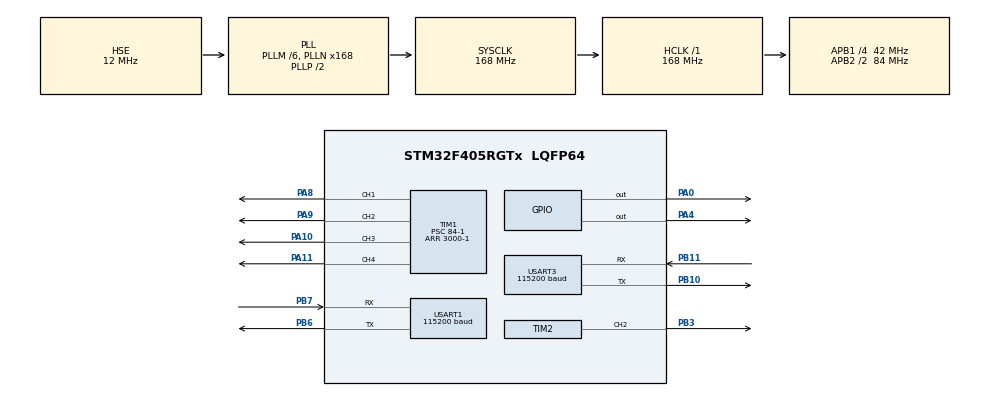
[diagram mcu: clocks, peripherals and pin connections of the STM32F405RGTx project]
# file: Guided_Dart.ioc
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Dma.Request0=USART3_RX
Dma.Request1=USART3_TX
Dma.Request2=USART1_RX
Dma.Request3=USART1_TX
Dma.USART1_RX.2.Direction=DMA_PERIPH_TO_MEMORY
Dma.USART1_RX.2.FIFOMode=DMA_FIFOMODE_DISABLE
Dma.USART1_RX.2.Instance=DMA2_Stream2
Dma.USART1_RX.2.MemDataAlignment=DMA_MDATAALIGN_BYTE
Dma.USART1_RX.2.MemInc=DMA_MINC_ENABLE
Dma.USART1_RX.2.Mode=DMA_NORMAL
Dma.USART1_RX.2.PeriphDataAlignment=DMA_PDATAALIGN_BYTE
Dma.USART1_RX.2.PeriphInc=DMA_PINC_DISABLE
Dma.USART1_RX.2.Priority=DMA_PRIORITY_LOW
Dma.USART1_TX.3.Direction=DMA_MEMORY_TO_PERIPH
Dma.USART1_TX.3.FIFOMode=DMA_FIFOMODE_DISABLE
Dma.USART1_TX.3.Instance=DMA2_Stream7
Dma.USART1_TX.3.MemDataAlignment=DMA_MDATAALIGN_BYTE
Dma.USART1_TX.3.MemInc=DMA_MINC_ENABLE
Dma.USART1_TX.3.Mode=DMA_NORMAL
Dma.USART1_TX.3.PeriphDataAlignment=DMA_PDATAALIGN_BYTE
Dma.USART1_TX.3.PeriphInc=DMA_PINC_DISABLE
Dma.USART1_TX.3.Priority=DMA_PRIORITY_LOW
Dma.USART3_RX.0.Direction=DMA_PERIPH_TO_MEMORY
Dma.USART3_RX.0.FIFOMode=DMA_FIFOMODE_DISABLE
Dma.USART3_RX.0.Instance=DMA1_Stream1
Dma.USART3_RX.0.MemDataAlignment=DMA_MDATAALIGN_BYTE
Dma.USART3_RX.0.MemInc=DMA_MINC_ENABLE
Dma.USART3_RX.0.Mode=DMA_NORMAL
Dma.USART3_RX.0.PeriphDataAlignment=DMA_PDATAALIGN_BYTE
Dma.USART3_RX.0.PeriphInc=DMA_PINC_DISABLE
Dma.USART3_RX.0.Priority=DMA_PRIORITY_LOW
Dma.USART3_TX.1.Direction=DMA_MEMORY_TO_PERIPH
Dma.USART3_TX.1.FIFOMode=DMA_FIFOMODE_DISABLE
Dma.USART3_TX.1.Instance=DMA1_Stream3
Dma.USART3_TX.1.MemDataAlignment=DMA_MDATAALIGN_BYTE
Dma.USART3_TX.1.MemInc=DMA_MINC_ENABLE
Dma.USART3_TX.1.Mode=DMA_NORMAL
Dma.USART3_TX.1.PeriphDataAlignment=DMA_PDATAALIGN_BYTE
Dma.USART3_TX.1.PeriphInc=DMA_PINC_DISABLE
Dma.USART3_TX.1.Priority=DMA_PRIORITY_LOW
Mcu.Family=STM32F4
Mcu.Name=STM32F405RGTx
Mcu.Package=LQFP64
NVIC.DMA1_Stream1_IRQn=true\:0\:0\:false\:false\:true\:false\:true\:true
NVIC.DMA1_Stream3_IRQn=true\:0\:0\:false\:false\:true\:false\:true\:true
NVIC.DMA2_Stream2_IRQn=true\:0\:0\:false\:false\:true\:false\:true\:true
NVIC.DMA2_Stream7_IRQn=true\:0\:0\:false\:false\:true\:false\:true\:true
NVIC.PriorityGroup=NVIC_PRIORITYGROUP_4
NVIC.USART1_IRQn=true\:0\:0\:false\:false\:true\:true\:true\:true
NVIC.USART3_IRQn=true\:0\:0\:false\:false\:true\:true\:true\:true
PA0-WKUP.GPIO_PuPd=GPIO_PULLDOWN
PA0-WKUP.PinState=GPIO_PIN_SET
PA0-WKUP.Signal=GPIO_Output
PA10.Signal=S_TIM1_CH3
PA11.Signal=S_TIM1_CH4
PA13.Mode=Serial_Wire
PA13.Signal=SYS_JTMS-SWDIO
PA14.Mode=Serial_Wire
PA14.Signal=SYS_JTCK-SWCLK
PA4.GPIO_PuPd=GPIO_PULLDOWN
PA4.GPIO_Speed=GPIO_SPEED_FREQ_VERY_HIGH
PA4.Signal=GPIO_Output
PA8.Signal=S_TIM1_CH1
PA9.Signal=S_TIM1_CH2
PB10.Mode=Asynchronous
PB10.Signal=USART3_TX
PB11.Mode=Asynchronous
PB11.Signal=USART3_RX
PB3.Signal=S_TIM2_CH2
PB6.Mode=Asynchronous
PB6.Signal=USART1_TX
PB7.Mode=Asynchronous
PB7.Signal=USART1_RX
PH0-OSC_IN.Mode=HSE-External-Oscillator
PH0-OSC_IN.Signal=RCC_OSC_IN
PH1-OSC_OUT.Mode=HSE-External-Oscillator
PH1-OSC_OUT.Signal=RCC_OSC_OUT
ProjectManager.HeapSize=0x200
ProjectManager.StackSize=0x400
ProjectManager.TargetToolchain=Makefile
RCC.48MHZClocksFreq_Value=84000000
RCC.AHBFreq_Value=168000000
RCC.APB1CLKDivider=RCC_HCLK_DIV4
RCC.APB1Freq_Value=42000000
RCC.APB1TimFreq_Value=84000000
RCC.APB2CLKDivider=RCC_HCLK_DIV2
RCC.APB2Freq_Value=84000000
RCC.APB2TimFreq_Value=168000000
RCC.CortexFreq_Value=168000000
RCC.HCLKFreq_Value=168000000
RCC.HSE_VALUE=12000000
RCC.HSI_VALUE=16000000
RCC.LSE_VALUE=32768
RCC.PLLM=6
RCC.PLLN=168
RCC.PLLSourceVirtual=RCC_PLLSOURCE_HSE
RCC.SYSCLKFreq_VALUE=168000000
RCC.SYSCLKSource=RCC_SYSCLKSOURCE_PLLCLK
RCC.VCOOutputFreq_Value=336000000
SH.S_TIM1_CH1.0=TIM1_CH1,PWM Generation1 CH1
SH.S_TIM1_CH2.0=TIM1_CH2,PWM Generation2 CH2
SH.S_TIM1_CH3.0=TIM1_CH3,PWM Generation3 CH3
SH.S_TIM1_CH4.0=TIM1_CH4,PWM Generation4 CH4
SH.S_TIM2_CH2.0=TIM2_CH2,PWM Generation2 CH2
STMicroelectronics.X-CUBE-ALGOBUILD.1.4.0.LibraryCcDSPOoLibraryJjDSPOoLibrary=true
TIM1.Channel-PWM\ Generation1\ CH1=TIM_CHANNEL_1
TIM1.Channel-PWM\ Generation2\ CH2=TIM_CHANNEL_2
TIM1.Channel-PWM\ Generation3\ CH3=TIM_CHANNEL_3
TIM1.Channel-PWM\ Generation4\ CH4=TIM_CHANNEL_4
TIM1.Period=3000-1
TIM1.Prescaler=84-1
TIM2.Channel-PWM\ Generation2\ CH2=TIM_CHANNEL_2
TIM2.Period=20000-1
TIM2.Prescaler=84-1
USART1.BaudRate=115200
USART1.VirtualMode=VM_ASYNC
USART3.BaudRate=115200
USART3.VirtualMode=VM_ASYNC
VP_STMicroelectronics.X-CUBE-ALGOBUILD_VS_DSPOoLibraryJjLibrary_1.4.0_1.4.0.Mode=DSPOoLibraryJjLibrary
VP_TIM1_VS_ClockSourceINT.Mode=Internal
VP_TIM2_VS_ClockSourceINT.Mode=Internal
board=custom

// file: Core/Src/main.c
/* USER CODE BEGIN Header */
/**
  ******************************************************************************
  * @file           : main.c
  * @brief          : Main program body
  ******************************************************************************
  * @attention
  *
  * <h2><center>&copy; Copyright (c) 2025 STMicroelectronics.
  * All rights reserved.</center></h2>
  *
  * This software component is licensed by ST under BSD 3-Clause license,
  * the "License"; You may not use this file except in compliance with the
  * License. You may obtain a copy of the License at:
  *                        opensource.org/licenses/BSD-3-Clause
  *
  ******************************************************************************
  */
/* USER CODE END Header */
#include "main.h"
#include "dma.h"
#include "tim.h"
#include "usart.h"
#include "gpio.h"

/* USER CODE BEGIN Includes */
#include "JY61P.h"  // 传感器头文件
#include "servo_motor.h" // 舵机头文�?
#include"openmv.h" // openmv头文�?
#include"Ducted_fan_Motor.h" // 电机头文�?
/* USER CODE END Includes */

void SystemClock_Config(void);

int main(void)
{

  /* MCU Configuration--------------------------------------------------------*/

  /* Reset of all peripherals, Initializes the Flash interface and the Systick. */
  HAL_Init();

  /* Configure the system clock */
  SystemClock_Config();

  /* Initialize all configured peripherals */
  MX_GPIO_Init();
  MX_DMA_Init();
  MX_USART3_UART_Init();
  MX_TIM1_Init();
  MX_USART1_UART_Init();
  MX_TIM2_Init();

  /* Infinite loop */
  /* USER CODE BEGIN WHILE */
  while (1)
  {
    // Servo_Motor_Task(0, 0, 0, 0); // 舵机任务
    /* USER CODE END WHILE */

  }
}

void SystemClock_Config(void)
{
  RCC_OscInitTypeDef RCC_OscInitStruct = {0};
  RCC_ClkInitTypeDef RCC_ClkInitStruct = {0};

  /** Configure the main internal regulator output voltage
  */
  __HAL_RCC_PWR_CLK_ENABLE();
  __HAL_PWR_VOLTAGESCALING_CONFIG(PWR_REGULATOR_VOLTAGE_SCALE1);

  /** Initializes the RCC Oscillators according to the specified parameters
  * in the RCC_OscInitTypeDef structure.
  */
  RCC_OscInitStruct.OscillatorType = RCC_OSCILLATORTYPE_HSE;
  RCC_OscInitStruct.HSEState = RCC_HSE_ON;
  RCC_OscInitStruct.PLL.PLLState = RCC_PLL_ON;
  RCC_OscInitStruct.PLL.PLLSource = RCC_PLLSOURCE_HSE;
  RCC_OscInitStruct.PLL.PLLM = 6;
  RCC_OscInitStruct.PLL.PLLN = 168;
  RCC_OscInitStruct.PLL.PLLP = RCC_PLLP_DIV2;
  RCC_OscInitStruct.PLL.PLLQ = 4;
  if (HAL_RCC_OscConfig(&RCC_OscInitStruct) != HAL_OK)
  {
    Error_Handler();
  }

  /** Initializes the CPU, AHB and APB buses clocks
  */
  RCC_ClkInitStruct.ClockType = RCC_CLOCKTYPE_HCLK|RCC_CLOCKTYPE_SYSCLK
                              |RCC_CLOCKTYPE_PCLK1|RCC_CLOCKTYPE_PCLK2;
  RCC_ClkInitStruct.SYSCLKSource = RCC_SYSCLKSOURCE_PLLCLK;
  RCC_ClkInitStruct.AHBCLKDivider = RCC_SYSCLK_DIV1;
  RCC_ClkInitStruct.APB1CLKDivider = RCC_HCLK_DIV4;
  RCC_ClkInitStruct.APB2CLKDivider = RCC_HCLK_DIV2;

  if (HAL_RCC_ClockConfig(&RCC_ClkInitStruct, FLASH_LATENCY_5) != HAL_OK)
  {
    Error_Handler();
  }
}

void Error_Handler(void)
{
  __disable_irq();
  while (1)
  {
  }
}
